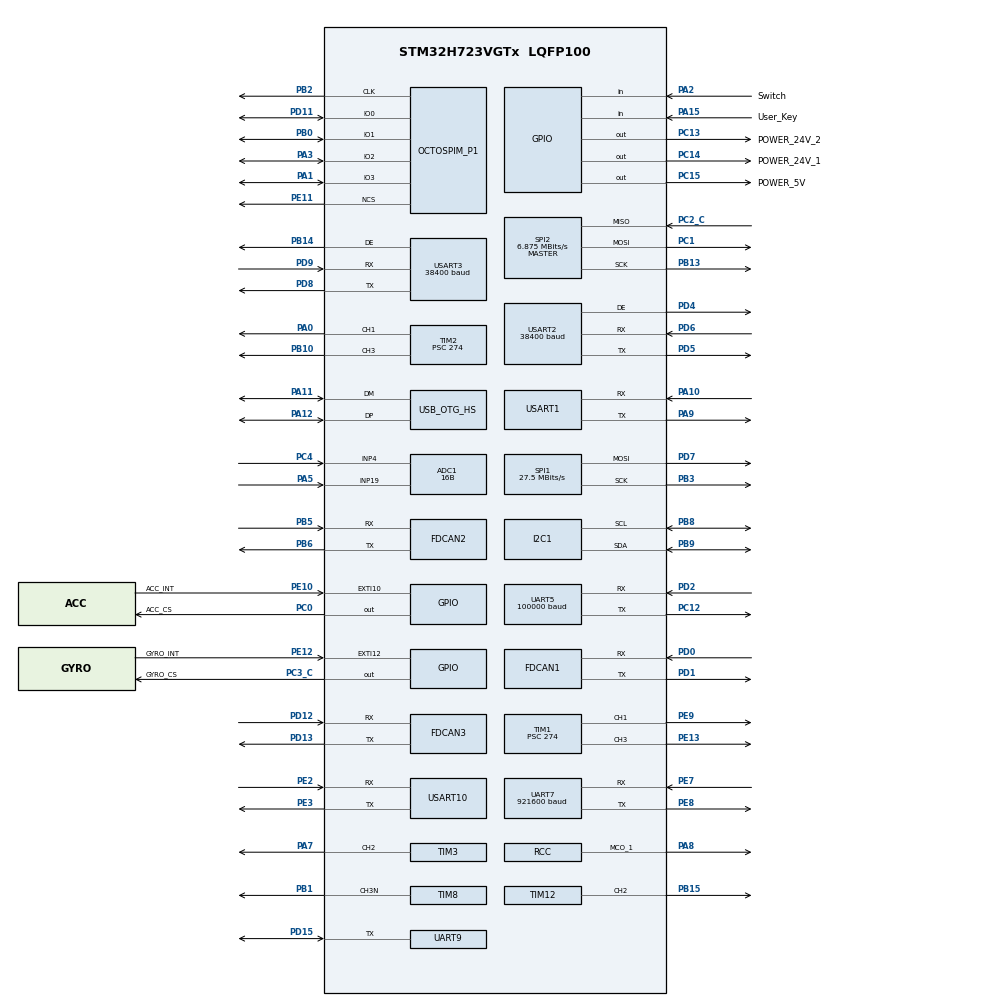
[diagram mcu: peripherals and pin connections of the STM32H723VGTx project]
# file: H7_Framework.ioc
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ADC1.Channel-0\#ChannelRegularConversion=ADC_CHANNEL_4
ADC1.Channel-1\#ChannelRegularConversion=ADC_CHANNEL_4
ADC1.ClockPrescaler=ADC_CLOCK_ASYNC_DIV64
ADC1.ContinuousConvMode=ENABLE
ADC1.DiscontinuousConvMode=DISABLE
ADC1.NbrOfConversion=2
ADC1.NbrOfConversionFlag=1
ADC1.OffsetNumber-0\#ChannelRegularConversion=ADC_OFFSET_NONE
ADC1.OffsetNumber-1\#ChannelRegularConversion=ADC_OFFSET_NONE
ADC1.OffsetSignedSaturation-0\#ChannelRegularConversion=DISABLE
ADC1.OffsetSignedSaturation-1\#ChannelRegularConversion=DISABLE
ADC1.Rank-0\#ChannelRegularConversion=1
ADC1.Rank-1\#ChannelRegularConversion=2
ADC1.Resolution=ADC_RESOLUTION_16B
ADC1.SamplingTime-0\#ChannelRegularConversion=ADC_SAMPLETIME_64CYCLES_5
ADC1.SamplingTime-1\#ChannelRegularConversion=ADC_SAMPLETIME_64CYCLES_5
ADC1.master=1
CORTEX_M7.CPU_ICache=Enabled
CORTEX_M7.default_mode_Activation=0
Dma.Request0=UART5_RX
Dma.Request1=SPI2_RX
Dma.Request10=USART2_RX
Dma.Request11=USART3_RX
Dma.Request12=USART2_TX
Dma.Request13=USART3_TX
Dma.Request14=UART9_RX
Dma.Request15=UART9_TX
Dma.Request2=SPI2_TX
Dma.Request3=TIM3_CH2
Dma.Request4=USART1_RX
Dma.Request5=UART7_RX
Dma.Request6=USART10_TX
Dma.Request7=USART10_RX
Dma.Request8=USART1_TX
Dma.Request9=UART7_TX
Dma.SPI2_RX.1.Direction=DMA_PERIPH_TO_MEMORY
Dma.SPI2_RX.1.EventEnable=DISABLE
Dma.SPI2_RX.1.FIFOMode=DMA_FIFOMODE_DISABLE
Dma.SPI2_RX.1.Instance=DMA1_Stream3
Dma.SPI2_RX.1.MemDataAlignment=DMA_MDATAALIGN_BYTE
Dma.SPI2_RX.1.MemInc=DMA_MINC_ENABLE
Dma.SPI2_RX.1.Mode=DMA_NORMAL
Dma.SPI2_RX.1.PeriphDataAlignment=DMA_PDATAALIGN_BYTE
Dma.SPI2_RX.1.PeriphInc=DMA_PINC_DISABLE
Dma.SPI2_RX.1.Polarity=HAL_DMAMUX_REQ_GEN_RISING
Dma.SPI2_RX.1.Priority=DMA_PRIORITY_VERY_HIGH
Dma.SPI2_RX.1.RequestNumber=1
Dma.SPI2_RX.1.SignalID=NONE
Dma.SPI2_RX.1.SyncEnable=DISABLE
Dma.SPI2_RX.1.SyncPolarity=HAL_DMAMUX_SYNC_NO_EVENT
Dma.SPI2_RX.1.SyncRequestNumber=1
Dma.SPI2_RX.1.SyncSignalID=NONE
Dma.SPI2_TX.2.Direction=DMA_MEMORY_TO_PERIPH
Dma.SPI2_TX.2.EventEnable=DISABLE
Dma.SPI2_TX.2.FIFOMode=DMA_FIFOMODE_DISABLE
Dma.SPI2_TX.2.Instance=DMA1_Stream4
Dma.SPI2_TX.2.MemDataAlignment=DMA_MDATAALIGN_BYTE
Dma.SPI2_TX.2.MemInc=DMA_MINC_ENABLE
Dma.SPI2_TX.2.Mode=DMA_NORMAL
Dma.SPI2_TX.2.PeriphDataAlignment=DMA_PDATAALIGN_BYTE
Dma.SPI2_TX.2.PeriphInc=DMA_PINC_DISABLE
Dma.SPI2_TX.2.Polarity=HAL_DMAMUX_REQ_GEN_RISING
Dma.SPI2_TX.2.Priority=DMA_PRIORITY_HIGH
Dma.SPI2_TX.2.RequestNumber=1
Dma.SPI2_TX.2.SignalID=NONE
Dma.SPI2_TX.2.SyncEnable=DISABLE
Dma.SPI2_TX.2.SyncPolarity=HAL_DMAMUX_SYNC_NO_EVENT
Dma.SPI2_TX.2.SyncRequestNumber=1
Dma.SPI2_TX.2.SyncSignalID=NONE
Dma.TIM3_CH2.3.Direction=DMA_MEMORY_TO_PERIPH
Dma.TIM3_CH2.3.EventEnable=DISABLE
Dma.TIM3_CH2.3.FIFOMode=DMA_FIFOMODE_DISABLE
Dma.TIM3_CH2.3.Instance=DMA1_Stream1
Dma.TIM3_CH2.3.MemDataAlignment=DMA_MDATAALIGN_HALFWORD
Dma.TIM3_CH2.3.MemInc=DMA_MINC_ENABLE
Dma.TIM3_CH2.3.Mode=DMA_CIRCULAR
Dma.TIM3_CH2.3.PeriphDataAlignment=DMA_PDATAALIGN_HALFWORD
Dma.TIM3_CH2.3.PeriphInc=DMA_PINC_DISABLE
Dma.TIM3_CH2.3.Polarity=HAL_DMAMUX_REQ_GEN_RISING
Dma.TIM3_CH2.3.Priority=DMA_PRIORITY_LOW
Dma.TIM3_CH2.3.RequestNumber=1
Dma.TIM3_CH2.3.SignalID=NONE
Dma.TIM3_CH2.3.SyncEnable=DISABLE
Dma.TIM3_CH2.3.SyncPolarity=HAL_DMAMUX_SYNC_NO_EVENT
Dma.TIM3_CH2.3.SyncRequestNumber=1
Dma.TIM3_CH2.3.SyncSignalID=NONE
Dma.UART5_RX.0.Direction=DMA_PERIPH_TO_MEMORY
Dma.UART5_RX.0.EventEnable=DISABLE
Dma.UART5_RX.0.FIFOMode=DMA_FIFOMODE_DISABLE
Dma.UART5_RX.0.Instance=DMA1_Stream0
Dma.UART5_RX.0.MemDataAlignment=DMA_MDATAALIGN_BYTE
Dma.UART5_RX.0.MemInc=DMA_MINC_ENABLE
Dma.UART5_RX.0.Mode=DMA_NORMAL
Dma.UART5_RX.0.PeriphDataAlignment=DMA_PDATAALIGN_BYTE
Dma.UART5_RX.0.PeriphInc=DMA_PINC_DISABLE
Dma.UART5_RX.0.Polarity=HAL_DMAMUX_REQ_GEN_RISING
Dma.UART5_RX.0.Priority=DMA_PRIORITY_HIGH
Dma.UART5_RX.0.RequestNumber=1
Dma.UART5_RX.0.SignalID=NONE
Dma.UART5_RX.0.SyncEnable=DISABLE
Dma.UART5_RX.0.SyncPolarity=HAL_DMAMUX_SYNC_NO_EVENT
Dma.UART5_RX.0.SyncRequestNumber=1
Dma.UART5_RX.0.SyncSignalID=NONE
Dma.UART7_RX.5.Direction=DMA_PERIPH_TO_MEMORY
Dma.UART7_RX.5.EventEnable=DISABLE
Dma.UART7_RX.5.FIFOMode=DMA_FIFOMODE_DISABLE
Dma.UART7_RX.5.Instance=DMA1_Stream5
Dma.UART7_RX.5.MemDataAlignment=DMA_MDATAALIGN_BYTE
Dma.UART7_RX.5.MemInc=DMA_MINC_ENABLE
Dma.UART7_RX.5.Mode=DMA_NORMAL
Dma.UART7_RX.5.PeriphDataAlignment=DMA_PDATAALIGN_BYTE
Dma.UART7_RX.5.PeriphInc=DMA_PINC_DISABLE
Dma.UART7_RX.5.Polarity=HAL_DMAMUX_REQ_GEN_RISING
Dma.UART7_RX.5.Priority=DMA_PRIORITY_LOW
Dma.UART7_RX.5.RequestNumber=1
Dma.UART7_RX.5.SignalID=NONE
Dma.UART7_RX.5.SyncEnable=DISABLE
Dma.UART7_RX.5.SyncPolarity=HAL_DMAMUX_SYNC_NO_EVENT
Dma.UART7_RX.5.SyncRequestNumber=1
Dma.UART7_RX.5.SyncSignalID=NONE
Dma.UART7_TX.9.Direction=DMA_MEMORY_TO_PERIPH
Dma.UART7_TX.9.EventEnable=DISABLE
Dma.UART7_TX.9.FIFOMode=DMA_FIFOMODE_DISABLE
Dma.UART7_TX.9.Instance=DMA2_Stream1
Dma.UART7_TX.9.MemDataAlignment=DMA_MDATAALIGN_BYTE
Dma.UART7_TX.9.MemInc=DMA_MINC_ENABLE
Dma.UART7_TX.9.Mode=DMA_NORMAL
Dma.UART7_TX.9.PeriphDataAlignment=DMA_PDATAALIGN_BYTE
Dma.UART7_TX.9.PeriphInc=DMA_PINC_DISABLE
Dma.UART7_TX.9.Polarity=HAL_DMAMUX_REQ_GEN_RISING
Dma.UART7_TX.9.Priority=DMA_PRIORITY_LOW
Dma.UART7_TX.9.RequestNumber=1
Dma.UART7_TX.9.SignalID=NONE
Dma.UART7_TX.9.SyncEnable=DISABLE
Dma.UART7_TX.9.SyncPolarity=HAL_DMAMUX_SYNC_NO_EVENT
Dma.UART7_TX.9.SyncRequestNumber=1
Dma.UART7_TX.9.SyncSignalID=NONE
Dma.UART9_RX.14.Direction=DMA_PERIPH_TO_MEMORY
Dma.UART9_RX.14.EventEnable=DISABLE
Dma.UART9_RX.14.FIFOMode=DMA_FIFOMODE_DISABLE
Dma.UART9_RX.14.Instance=DMA2_Stream6
Dma.UART9_RX.14.MemDataAlignment=DMA_MDATAALIGN_BYTE
Dma.UART9_RX.14.MemInc=DMA_MINC_ENABLE
Dma.UART9_RX.14.Mode=DMA_NORMAL
Dma.UART9_RX.14.PeriphDataAlignment=DMA_PDATAALIGN_BYTE
Dma.UART9_RX.14.PeriphInc=DMA_PINC_DISABLE
Dma.UART9_RX.14.Polarity=HAL_DMAMUX_REQ_GEN_RISING
Dma.UART9_RX.14.Priority=DMA_PRIORITY_HIGH
Dma.UART9_RX.14.RequestNumber=1
Dma.UART9_RX.14.SignalID=NONE
Dma.UART9_RX.14.SyncEnable=DISABLE
Dma.UART9_RX.14.SyncPolarity=HAL_DMAMUX_SYNC_NO_EVENT
Dma.UART9_RX.14.SyncRequestNumber=1
Dma.UART9_RX.14.SyncSignalID=NONE
Dma.UART9_TX.15.Direction=DMA_MEMORY_TO_PERIPH
Dma.UART9_TX.15.EventEnable=DISABLE
Dma.UART9_TX.15.FIFOMode=DMA_FIFOMODE_DISABLE
Dma.UART9_TX.15.Instance=DMA2_Stream7
Dma.UART9_TX.15.MemDataAlignment=DMA_MDATAALIGN_BYTE
Dma.UART9_TX.15.MemInc=DMA_MINC_ENABLE
Dma.UART9_TX.15.Mode=DMA_NORMAL
Dma.UART9_TX.15.PeriphDataAlignment=DMA_PDATAALIGN_BYTE
Dma.UART9_TX.15.PeriphInc=DMA_PINC_DISABLE
Dma.UART9_TX.15.Polarity=HAL_DMAMUX_REQ_GEN_RISING
Dma.UART9_TX.15.Priority=DMA_PRIORITY_HIGH
Dma.UART9_TX.15.RequestNumber=1
Dma.UART9_TX.15.SignalID=NONE
Dma.UART9_TX.15.SyncEnable=DISABLE
Dma.UART9_TX.15.SyncPolarity=HAL_DMAMUX_SYNC_NO_EVENT
Dma.UART9_TX.15.SyncRequestNumber=1
Dma.UART9_TX.15.SyncSignalID=NONE
Dma.USART10_RX.7.Direction=DMA_PERIPH_TO_MEMORY
Dma.USART10_RX.7.EventEnable=DISABLE
Dma.USART10_RX.7.FIFOMode=DMA_FIFOMODE_DISABLE
Dma.USART10_RX.7.Instance=DMA1_Stream7
Dma.USART10_RX.7.MemDataAlignment=DMA_MDATAALIGN_BYTE
Dma.USART10_RX.7.MemInc=DMA_MINC_ENABLE
Dma.USART10_RX.7.Mode=DMA_NORMAL
Dma.USART10_RX.7.PeriphDataAlignment=DMA_PDATAALIGN_BYTE
Dma.USART10_RX.7.PeriphInc=DMA_PINC_DISABLE
Dma.USART10_RX.7.Polarity=HAL_DMAMUX_REQ_GEN_RISING
Dma.USART10_RX.7.Priority=DMA_PRIORITY_LOW
Dma.USART10_RX.7.RequestNumber=1
Dma.USART10_RX.7.SignalID=NONE
Dma.USART10_RX.7.SyncEnable=DISABLE
Dma.USART10_RX.7.SyncPolarity=HAL_DMAMUX_SYNC_NO_EVENT
Dma.USART10_RX.7.SyncRequestNumber=1
Dma.USART10_RX.7.SyncSignalID=NONE
Dma.USART10_TX.6.Direction=DMA_MEMORY_TO_PERIPH
Dma.USART10_TX.6.EventEnable=DISABLE
Dma.USART10_TX.6.FIFOMode=DMA_FIFOMODE_DISABLE
Dma.USART10_TX.6.Instance=DMA1_Stream6
Dma.USART10_TX.6.MemDataAlignment=DMA_MDATAALIGN_BYTE
Dma.USART10_TX.6.MemInc=DMA_MINC_ENABLE
Dma.USART10_TX.6.Mode=DMA_NORMAL
Dma.USART10_TX.6.PeriphDataAlignment=DMA_PDATAALIGN_BYTE
Dma.USART10_TX.6.PeriphInc=DMA_PINC_DISABLE
Dma.USART10_TX.6.Polarity=HAL_DMAMUX_REQ_GEN_RISING
Dma.USART10_TX.6.Priority=DMA_PRIORITY_LOW
Dma.USART10_TX.6.RequestNumber=1
Dma.USART10_TX.6.SignalID=NONE
Dma.USART10_TX.6.SyncEnable=DISABLE
Dma.USART10_TX.6.SyncPolarity=HAL_DMAMUX_SYNC_NO_EVENT
Dma.USART10_TX.6.SyncRequestNumber=1
Dma.USART10_TX.6.SyncSignalID=NONE
Dma.USART1_RX.4.Direction=DMA_PERIPH_TO_MEMORY
Dma.USART1_RX.4.EventEnable=DISABLE
Dma.USART1_RX.4.FIFOMode=DMA_FIFOMODE_DISABLE
Dma.USART1_RX.4.Instance=DMA1_Stream2
Dma.USART1_RX.4.MemDataAlignment=DMA_MDATAALIGN_BYTE
Dma.USART1_RX.4.MemInc=DMA_MINC_ENABLE
Dma.USART1_RX.4.Mode=DMA_NORMAL
Dma.USART1_RX.4.PeriphDataAlignment=DMA_PDATAALIGN_BYTE
Dma.USART1_RX.4.PeriphInc=DMA_PINC_DISABLE
Dma.USART1_RX.4.Polarity=HAL_DMAMUX_REQ_GEN_RISING
Dma.USART1_RX.4.Priority=DMA_PRIORITY_LOW
Dma.USART1_RX.4.RequestNumber=1
Dma.USART1_RX.4.SignalID=NONE
Dma.USART1_RX.4.SyncEnable=DISABLE
Dma.USART1_RX.4.SyncPolarity=HAL_DMAMUX_SYNC_NO_EVENT
Dma.USART1_RX.4.SyncRequestNumber=1
Dma.USART1_RX.4.SyncSignalID=NONE
Dma.USART1_TX.8.Direction=DMA_MEMORY_TO_PERIPH
Dma.USART1_TX.8.EventEnable=DISABLE
Dma.USART1_TX.8.FIFOMode=DMA_FIFOMODE_DISABLE
Dma.USART1_TX.8.Instance=DMA2_Stream0
Dma.USART1_TX.8.MemDataAlignment=DMA_MDATAALIGN_BYTE
Dma.USART1_TX.8.MemInc=DMA_MINC_ENABLE
Dma.USART1_TX.8.Mode=DMA_NORMAL
Dma.USART1_TX.8.PeriphDataAlignment=DMA_PDATAALIGN_BYTE
Dma.USART1_TX.8.PeriphInc=DMA_PINC_DISABLE
Dma.USART1_TX.8.Polarity=HAL_DMAMUX_REQ_GEN_RISING
Dma.USART1_TX.8.Priority=DMA_PRIORITY_LOW
Dma.USART1_TX.8.RequestNumber=1
Dma.USART1_TX.8.SignalID=NONE
Dma.USART1_TX.8.SyncEnable=DISABLE
Dma.USART1_TX.8.SyncPolarity=HAL_DMAMUX_SYNC_NO_EVENT
Dma.USART1_TX.8.SyncRequestNumber=1
Dma.USART1_TX.8.SyncSignalID=NONE
Dma.USART2_RX.10.Direction=DMA_PERIPH_TO_MEMORY
Dma.USART2_RX.10.EventEnable=DISABLE
Dma.USART2_RX.10.FIFOMode=DMA_FIFOMODE_DISABLE
Dma.USART2_RX.10.Instance=DMA2_Stream2
Dma.USART2_RX.10.MemDataAlignment=DMA_MDATAALIGN_BYTE
Dma.USART2_RX.10.MemInc=DMA_MINC_ENABLE
Dma.USART2_RX.10.Mode=DMA_NORMAL
Dma.USART2_RX.10.PeriphDataAlignment=DMA_PDATAALIGN_BYTE
Dma.USART2_RX.10.PeriphInc=DMA_PINC_DISABLE
Dma.USART2_RX.10.Polarity=HAL_DMAMUX_REQ_GEN_RISING
Dma.USART2_RX.10.Priority=DMA_PRIORITY_HIGH
Dma.USART2_RX.10.RequestNumber=1
Dma.USART2_RX.10.SignalID=NONE
Dma.USART2_RX.10.SyncEnable=DISABLE
Dma.USART2_RX.10.SyncPolarity=HAL_DMAMUX_SYNC_NO_EVENT
Dma.USART2_RX.10.SyncRequestNumber=1
Dma.USART2_RX.10.SyncSignalID=NONE
Dma.USART2_TX.12.Direction=DMA_MEMORY_TO_PERIPH
Dma.USART2_TX.12.EventEnable=DISABLE
Dma.USART2_TX.12.FIFOMode=DMA_FIFOMODE_DISABLE
Dma.USART2_TX.12.Instance=DMA2_Stream4
Dma.USART2_TX.12.MemDataAlignment=DMA_MDATAALIGN_BYTE
Dma.USART2_TX.12.MemInc=DMA_MINC_ENABLE
Dma.USART2_TX.12.Mode=DMA_NORMAL
Dma.USART2_TX.12.PeriphDataAlignment=DMA_PDATAALIGN_BYTE
Dma.USART2_TX.12.PeriphInc=DMA_PINC_DISABLE
Dma.USART2_TX.12.Polarity=HAL_DMAMUX_REQ_GEN_RISING
Dma.USART2_TX.12.Priority=DMA_PRIORITY_LOW
Dma.USART2_TX.12.RequestNumber=1
Dma.USART2_TX.12.SignalID=NONE
Dma.USART2_TX.12.SyncEnable=DISABLE
Dma.USART2_TX.12.SyncPolarity=HAL_DMAMUX_SYNC_NO_EVENT
Dma.USART2_TX.12.SyncRequestNumber=1
Dma.USART2_TX.12.SyncSignalID=NONE
Dma.USART3_RX.11.Direction=DMA_PERIPH_TO_MEMORY
Dma.USART3_RX.11.EventEnable=DISABLE
Dma.USART3_RX.11.FIFOMode=DMA_FIFOMODE_DISABLE
Dma.USART3_RX.11.Instance=DMA2_Stream3
Dma.USART3_RX.11.MemDataAlignment=DMA_MDATAALIGN_BYTE
Dma.USART3_RX.11.MemInc=DMA_MINC_ENABLE
Dma.USART3_RX.11.Mode=DMA_NORMAL
Dma.USART3_RX.11.PeriphDataAlignment=DMA_PDATAALIGN_BYTE
Dma.USART3_RX.11.PeriphInc=DMA_PINC_DISABLE
Dma.USART3_RX.11.Polarity=HAL_DMAMUX_REQ_GEN_RISING
Dma.USART3_RX.11.Priority=DMA_PRIORITY_HIGH
Dma.USART3_RX.11.RequestNumber=1
Dma.USART3_RX.11.SignalID=NONE
Dma.USART3_RX.11.SyncEnable=DISABLE
Dma.USART3_RX.11.SyncPolarity=HAL_DMAMUX_SYNC_NO_EVENT
Dma.USART3_RX.11.SyncRequestNumber=1
Dma.USART3_RX.11.SyncSignalID=NONE
Dma.USART3_TX.13.Direction=DMA_MEMORY_TO_PERIPH
Dma.USART3_TX.13.EventEnable=DISABLE
Dma.USART3_TX.13.FIFOMode=DMA_FIFOMODE_DISABLE
Dma.USART3_TX.13.Instance=DMA2_Stream5
Dma.USART3_TX.13.MemDataAlignment=DMA_MDATAALIGN_BYTE
Dma.USART3_TX.13.MemInc=DMA_MINC_ENABLE
Dma.USART3_TX.13.Mode=DMA_NORMAL
Dma.USART3_TX.13.PeriphDataAlignment=DMA_PDATAALIGN_BYTE
Dma.USART3_TX.13.PeriphInc=DMA_PINC_DISABLE
Dma.USART3_TX.13.Polarity=HAL_DMAMUX_REQ_GEN_RISING
Dma.USART3_TX.13.Priority=DMA_PRIORITY_LOW
Dma.USART3_TX.13.RequestNumber=1
Dma.USART3_TX.13.SignalID=NONE
Dma.USART3_TX.13.SyncEnable=DISABLE
Dma.USART3_TX.13.SyncPolarity=HAL_DMAMUX_SYNC_NO_EVENT
Dma.USART3_TX.13.SyncRequestNumber=1
Dma.USART3_TX.13.SyncSignalID=NONE
FDCAN1.AutoRetransmission=ENABLE
FDCAN1.CalculateBaudRateNominal=999999
FDCAN1.CalculateTimeBitNominal=1000
FDCAN1.CalculateTimeQuantumNominal=100.00000000000001
FDCAN1.DataTimeSeg1=16
FDCAN1.DataTimeSeg2=5
FDCAN1.NominalPrescaler=11
FDCAN1.NominalTimeSeg1=7
FDCAN1.NominalTimeSeg2=2
FDCAN1.ProtocolException=ENABLE
FDCAN1.RxBufferSize=FDCAN_DATA_BYTES_64
FDCAN1.RxFifo0ElmtSize=FDCAN_DATA_BYTES_64
FDCAN1.RxFifo0ElmtsNbr=8
FDCAN1.RxFifo1ElmtSize=FDCAN_DATA_BYTES_64
FDCAN1.RxFifo1ElmtsNbr=0
FDCAN1.StdFiltersNbr=1
FDCAN1.TxElmtSize=FDCAN_DATA_BYTES_64
FDCAN1.TxFifoQueueElmtsNbr=8
FDCAN2.AutoRetransmission=ENABLE
FDCAN2.CalculateBaudRateNominal=999999
FDCAN2.CalculateTimeBitNominal=1000
FDCAN2.CalculateTimeQuantumNominal=100.00000000000001
FDCAN2.DataTimeSeg1=16
FDCAN2.DataTimeSeg2=5
FDCAN2.MessageRAMOffset=853
FDCAN2.NominalPrescaler=11
FDCAN2.NominalTimeSeg1=7
FDCAN2.NominalTimeSeg2=2
FDCAN2.ProtocolException=ENABLE
FDCAN2.RxBufferSize=FDCAN_DATA_BYTES_64
FDCAN2.RxFifo0ElmtSize=FDCAN_DATA_BYTES_64
FDCAN2.RxFifo0ElmtsNbr=0
FDCAN2.RxFifo1ElmtSize=FDCAN_DATA_BYTES_64
FDCAN2.RxFifo1ElmtsNbr=8
FDCAN2.StdFiltersNbr=1
FDCAN2.TxElmtSize=FDCAN_DATA_BYTES_64
FDCAN2.TxFifoQueueElmtsNbr=8
FDCAN3.AutoRetransmission=ENABLE
FDCAN3.CalculateBaudRateNominal=999999
FDCAN3.CalculateTimeBitNominal=1000
FDCAN3.CalculateTimeQuantumNominal=100.00000000000001
FDCAN3.DataTimeSeg1=16
FDCAN3.DataTimeSeg2=5
FDCAN3.MessageRAMOffset=1706
FDCAN3.NominalPrescaler=11
FDCAN3.NominalTimeSeg1=7
FDCAN3.NominalTimeSeg2=2
FDCAN3.ProtocolException=ENABLE
FDCAN3.RxBufferSize=FDCAN_DATA_BYTES_64
FDCAN3.RxFifo0ElmtSize=FDCAN_DATA_BYTES_64
FDCAN3.RxFifo0ElmtsNbr=8
FDCAN3.RxFifo1ElmtSize=FDCAN_DATA_BYTES_64
FDCAN3.StdFiltersNbr=1
FDCAN3.TxElmtSize=FDCAN_DATA_BYTES_64
FDCAN3.TxFifoQueueElmtsNbr=8
FREERTOS.Tasks01=IMU,48,256,IMU_Task,As weak,NULL,Dynamic,NULL,NULL;Motor,32,256,Motor_Task,As weak,NULL,Dynamic,NULL,NULL;Command,41,128,Command_Task,As weak,NULL,Dynamic,NULL,NULL;Task01,25,512,StartTask01,As weak,NULL,Dynamic,NULL,NULL;Task02,26,512,StartTask02,As weak,NULL,Dynamic,NULL,NULL;RtosSnapshot,8,256,RtosSnapshotTask,As weak,NULL,Dynamic,NULL,NULL
I2C1.Timing=0x60404E72
Mcu.Family=STM32H7
Mcu.Name=STM32H723VGTx
Mcu.Package=LQFP100
NVIC.ADC_IRQn=true\:5\:0\:false\:false\:true\:true\:true\:true\:true
NVIC.DMA1_Stream0_IRQn=true\:5\:0\:false\:false\:true\:true\:false\:true\:true
NVIC.DMA1_Stream1_IRQn=true\:5\:0\:false\:false\:true\:true\:false\:true\:true
NVIC.DMA1_Stream2_IRQn=true\:5\:0\:false\:false\:true\:true\:false\:true\:true
NVIC.DMA1_Stream3_IRQn=true\:5\:0\:false\:false\:true\:true\:false\:true\:true
NVIC.DMA1_Stream4_IRQn=true\:5\:0\:false\:false\:true\:true\:false\:true\:true
NVIC.DMA1_Stream5_IRQn=true\:5\:0\:false\:false\:true\:true\:false\:true\:true
NVIC.DMA1_Stream6_IRQn=true\:5\:0\:false\:false\:true\:true\:false\:true\:true
NVIC.DMA1_Stream7_IRQn=true\:5\:0\:false\:false\:true\:true\:false\:true\:true
NVIC.DMA2_Stream0_IRQn=true\:5\:0\:false\:false\:true\:true\:false\:true\:true
NVIC.DMA2_Stream1_IRQn=true\:5\:0\:false\:false\:true\:true\:false\:true\:true
NVIC.DMA2_Stream2_IRQn=true\:5\:0\:false\:false\:true\:true\:false\:true\:true
NVIC.DMA2_Stream3_IRQn=true\:5\:0\:false\:false\:true\:true\:false\:true\:true
NVIC.DMA2_Stream4_IRQn=true\:5\:0\:false\:false\:true\:true\:false\:true\:true
NVIC.DMA2_Stream5_IRQn=true\:5\:0\:false\:false\:true\:true\:false\:true\:true
NVIC.DMA2_Stream6_IRQn=true\:5\:0\:false\:false\:true\:true\:false\:true\:true
NVIC.DMA2_Stream7_IRQn=true\:5\:0\:false\:false\:true\:true\:false\:true\:true
NVIC.EXTI15_10_IRQn=true\:5\:0\:false\:false\:true\:true\:true\:true\:true
NVIC.FDCAN1_IT0_IRQn=true\:5\:0\:false\:false\:true\:true\:true\:true\:true
NVIC.FDCAN1_IT1_IRQn=true\:5\:0\:false\:false\:true\:true\:true\:true\:true
NVIC.FDCAN2_IT0_IRQn=true\:5\:0\:false\:false\:true\:true\:true\:true\:true
NVIC.FDCAN2_IT1_IRQn=true\:5\:0\:false\:false\:true\:true\:true\:true\:true
NVIC.FDCAN3_IT0_IRQn=true\:5\:0\:false\:false\:true\:true\:true\:true\:true
NVIC.FDCAN3_IT1_IRQn=true\:5\:0\:false\:false\:true\:true\:true\:true\:true
NVIC.OTG_HS_IRQn=true\:5\:0\:false\:false\:true\:true\:false\:true\:true
NVIC.PriorityGroup=NVIC_PRIORITYGROUP_4
NVIC.SPI2_IRQn=true\:5\:0\:false\:false\:true\:true\:false\:true\:true
NVIC.TIM17_IRQn=true\:15\:0\:false\:false\:true\:false\:false\:true\:true
NVIC.TIM4_IRQn=true\:5\:0\:false\:false\:true\:true\:true\:true\:true
NVIC.TIM6_DAC_IRQn=true\:5\:0\:false\:false\:true\:true\:true\:true\:true
NVIC.TIM7_IRQn=true\:5\:0\:false\:false\:true\:true\:true\:true\:true
NVIC.TimeBase=TIM17_IRQn
NVIC.TimeBaseIP=TIM17
NVIC.UART5_IRQn=true\:5\:0\:false\:false\:true\:true\:true\:true\:true
NVIC.UART7_IRQn=true\:5\:0\:false\:false\:true\:true\:true\:true\:true
NVIC.UART9_IRQn=true\:5\:0\:false\:false\:true\:true\:true\:true\:true
NVIC.USART10_IRQn=true\:5\:0\:false\:false\:true\:true\:true\:true\:true
NVIC.USART1_IRQn=true\:5\:0\:false\:false\:true\:true\:true\:true\:true
NVIC.USART2_IRQn=true\:5\:0\:false\:false\:true\:true\:true\:true\:true
NVIC.USART3_IRQn=true\:5\:0\:false\:false\:true\:true\:true\:true\:true
OCTOSPI2.ClockMode=HAL_OSPI_CLOCK_MODE_3
OCTOSPI2.ClockPrescaler=3
OCTOSPI2.DeviceSize=23
OCTOSPI2.FifoThreshold=8
OCTOSPI2.SampleShifting=HAL_OSPI_SAMPLE_SHIFTING_HALFCYCLE
PA0.Signal=S_TIM2_CH1_ETR
PA1.Mode=OCTOSPI2_IOL_Port1L
PA1.Signal=OCTOSPIM_P1_IO3
PA10.Mode=Asynchronous
PA10.Signal=USART1_RX
PA11.Mode=Device_Only_FS
PA11.Signal=USB_OTG_HS_DM
PA12.Mode=Device_Only_FS
PA12.Signal=USB_OTG_HS_DP
PA13(JTMS/SWDIO).Mode=Serial_Wire
PA13(JTMS/SWDIO).Signal=DEBUG_JTMS-SWDIO
PA14(JTCK/SWCLK).Mode=Serial_Wire
PA14(JTCK/SWCLK).Signal=DEBUG_JTCK-SWCLK
PA15(JTDI).GPIO_Label=User_Key
PA15(JTDI).GPIO_PuPd=GPIO_PULLUP
PA15(JTDI).Signal=GPIO_Input
PA2.GPIO_Label=Switch
PA2.GPIO_PuPd=GPIO_PULLUP
PA2.Signal=GPIO_Input
PA3.Mode=OCTOSPI2_IOL_Port1L
PA3.Signal=OCTOSPIM_P1_IO2
PA5.Signal=ADCx_INP19
PA7.Signal=S_TIM3_CH2
PA8.Mode=Clock-out-1
PA8.Signal=RCC_MCO_1
PA9.Mode=Asynchronous
PA9.Signal=USART1_TX
PB0.Mode=OCTOSPI2_IOL_Port1L
PB0.Signal=OCTOSPIM_P1_IO1
PB1.Mode=PWM Generation3 CH3N
PB1.Signal=TIM8_CH3N
PB10.Signal=S_TIM2_CH3
PB13.Mode=Full_Duplex_Master
PB13.Signal=SPI2_SCK
PB14.Mode=Hardware Flow Control (RS485)
PB14.Signal=USART3_DE
PB15.Signal=S_TIM12_CH2
PB2.Mode=O2_P1_CLK
PB2.Signal=OCTOSPIM_P1_CLK
PB3(JTDO/TRACESWO).Mode=TX_Only_Simplex_Unidirect_Master
PB3(JTDO/TRACESWO).Signal=SPI1_SCK
PB5.GPIO_Speed=GPIO_SPEED_FREQ_VERY_HIGH
PB5.Mode=FDCAN_Activate
PB5.Signal=FDCAN2_RX
PB6.GPIO_Speed=GPIO_SPEED_FREQ_VERY_HIGH
PB6.Mode=FDCAN_Activate
PB6.Signal=FDCAN2_TX
PB8.Mode=I2C
PB8.Signal=I2C1_SCL
PB9.Mode=I2C
PB9.Signal=I2C1_SDA
PC0.GPIO_Label=ACC_CS
PC0.GPIO_Speed=GPIO_SPEED_FREQ_VERY_HIGH
PC0.PinState=GPIO_PIN_SET
PC0.Signal=GPIO_Output
PC1.Mode=Full_Duplex_Master
PC1.Signal=SPI2_MOSI
PC12.Mode=Asynchronous
PC12.Signal=UART5_TX
PC13.GPIO_Label=POWER_24V_2
PC13.PinState=GPIO_PIN_SET
PC13.Signal=GPIO_Output
PC14-OSC32_IN.GPIO_Label=POWER_24V_1
PC14-OSC32_IN.PinState=GPIO_PIN_SET
PC14-OSC32_IN.Signal=GPIO_Output
PC15-OSC32_OUT.GPIO_Label=POWER_5V
PC15-OSC32_OUT.Signal=GPIO_Output
PC2_C.Mode=Full_Duplex_Master
PC2_C.Signal=SPI2_MISO
PC3_C.GPIO_Label=GYRO_CS
PC3_C.GPIO_Speed=GPIO_SPEED_FREQ_VERY_HIGH
PC3_C.PinState=GPIO_PIN_SET
PC3_C.Signal=GPIO_Output
PC4.Signal=ADCx_INP4
PD0.GPIO_Speed=GPIO_SPEED_FREQ_VERY_HIGH
PD0.Mode=FDCAN_Activate
PD0.Signal=FDCAN1_RX
PD1.GPIO_Speed=GPIO_SPEED_FREQ_VERY_HIGH
PD1.Mode=FDCAN_Activate
PD1.Signal=FDCAN1_TX
PD11.Mode=OCTOSPI2_IOL_Port1L
PD11.Signal=OCTOSPIM_P1_IO0
PD12.GPIO_Speed=GPIO_SPEED_FREQ_VERY_HIGH
PD12.Mode=FDCAN_Activate
PD12.Signal=FDCAN3_RX
PD13.GPIO_Speed=GPIO_SPEED_FREQ_VERY_HIGH
PD13.Mode=FDCAN_Activate
PD13.Signal=FDCAN3_TX
PD15.GPIO_ModeDefaultOD=GPIO_MODE_AF_PP
PD15.GPIO_PuPd=GPIO_PULLUP
PD15.GPIO_Speed=GPIO_SPEED_FREQ_VERY_HIGH
PD15.Mode=Half_duplex(single_wire_mode)
PD15.Signal=UART9_TX
PD2.GPIO_PuPd=GPIO_PULLUP
PD2.GPIO_Speed=GPIO_SPEED_FREQ_HIGH
PD2.Mode=Asynchronous
PD2.Signal=UART5_RX
PD4.Mode=Hardware Flow Control (RS485)
PD4.Signal=USART2_DE
PD5.Mode=Asynchronous
PD5.Signal=USART2_TX
PD6.Mode=Asynchronous
PD6.Signal=USART2_RX
PD7.Mode=TX_Only_Simplex_Unidirect_Master
PD7.Signal=SPI1_MOSI
PD8.Mode=Asynchronous
PD8.Signal=USART3_TX
PD9.Mode=Asynchronous
PD9.Signal=USART3_RX
PE10.GPIO_Label=ACC_INT
PE10.GPIO_ModeDefaultEXTI=GPIO_MODE_IT_FALLING
PE10.Signal=GPXTI10
PE11.Mode=OCTOSPI2_Port1_NCS
PE11.Signal=OCTOSPIM_P1_NCS
PE12.GPIO_Label=GYRO_INT
PE12.GPIO_ModeDefaultEXTI=GPIO_MODE_IT_FALLING
PE12.GPIO_PuPd=GPIO_PULLUP
PE12.Signal=GPXTI12
PE13.Signal=S_TIM1_CH3
PE2.Mode=Asynchronous
PE2.Signal=USART10_RX
PE3.Mode=Asynchronous
PE3.Signal=USART10_TX
PE7.Mode=Asynchronous
PE7.Signal=UART7_RX
PE8.GPIO_PuPd=GPIO_PULLUP
PE8.GPIO_Speed=GPIO_SPEED_FREQ_VERY_HIGH
PE8.Mode=Asynchronous
PE8.Signal=UART7_TX
PE9.Signal=S_TIM1_CH1
PH0-OSC_IN.Mode=HSE-External-Oscillator
PH0-OSC_IN.Signal=RCC_OSC_IN
PH1-OSC_OUT.Mode=HSE-External-Oscillator
PH1-OSC_OUT.Signal=RCC_OSC_OUT
ProjectManager.HeapSize=0x400
ProjectManager.StackSize=0x800
ProjectManager.TargetToolchain=CMake
RCC.ADCFreq_Value=96000000
RCC.APB1Freq_Value=137500000
RCC.APB2Freq_Value=137500000
RCC.APB3Freq_Value=137500000
RCC.APB4Freq_Value=137500000
RCC.CortexFreq_Value=550000000
RCC.D1PPRE=RCC_APB3_DIV2
RCC.D2PPRE1=RCC_APB1_DIV2
RCC.D2PPRE2=RCC_APB2_DIV2
RCC.D3PPRE=RCC_APB4_DIV2
RCC.DIVM1=3
RCC.DIVM2=2
RCC.DIVN1=68
RCC.DIVN2=16
RCC.DIVP1=1
RCC.DIVQ1=5
RCC.HCLKFreq_Value=275000000
RCC.HPRE=RCC_HCLK_DIV2
RCC.HSE_VALUE=24000000
RCC.PLL2FRACN=0
RCC.PLL3FRACN=0
RCC.PLLFRACN=6144
RCC.PLLSourceVirtual=RCC_PLLSOURCE_HSE
RCC.SYSCLKFreq_VALUE=550000000
RCC.SYSCLKSource=RCC_SYSCLKSOURCE_PLLCLK
RCC.USBCLockSelection=RCC_USBCLKSOURCE_HSI48
RCC.USBFreq_Value=48000000
SH.ADCx_INP19.0=ADC1_INP19,IN19-Single-Ended
SH.ADCx_INP4.0=ADC1_INP4,IN4-Single-Ended
SH.S_TIM12_CH2.0=TIM12_CH2,PWM Generation2 CH2
SH.S_TIM1_CH1.0=TIM1_CH1,PWM Generation1 CH1
SH.S_TIM1_CH3.0=TIM1_CH3,PWM Generation3 CH3
SH.S_TIM2_CH1_ETR.0=TIM2_CH1,PWM Generation1 CH1
SH.S_TIM2_CH3.0=TIM2_CH3,PWM Generation3 CH3
SH.S_TIM3_CH2.0=TIM3_CH2,PWM Generation2 CH2
SPI1.BaudRatePrescaler=SPI_BAUDRATEPRESCALER_4
SPI1.CLKPolarity=SPI_POLARITY_HIGH
SPI1.CalculateBaudRate=27.5 MBits/s
SPI1.DataSize=SPI_DATASIZE_8BIT
SPI1.Direction=SPI_DIRECTION_2LINES_TXONLY
SPI1.Mode=SPI_MODE_MASTER
SPI1.VirtualType=VM_MASTER
SPI2.BaudRatePrescaler=SPI_BAUDRATEPRESCALER_16
SPI2.CLKPhase=SPI_PHASE_2EDGE
SPI2.CLKPolarity=SPI_POLARITY_HIGH
SPI2.CalculateBaudRate=6.875 MBits/s
SPI2.DataSize=SPI_DATASIZE_8BIT
SPI2.Direction=SPI_DIRECTION_2LINES
SPI2.Mode=SPI_MODE_MASTER
SPI2.NSSPMode=SPI_NSS_PULSE_ENABLE
SPI2.VirtualType=VM_MASTER
TIM1.Channel-PWM\ Generation1\ CH1=TIM_CHANNEL_1
TIM1.Channel-PWM\ Generation3\ CH3=TIM_CHANNEL_3
TIM1.Period=19999
TIM1.Prescaler=274
TIM12.AutoReloadPreload=TIM_AUTORELOAD_PRELOAD_ENABLE
TIM12.Channel-PWM\ Generation2\ CH2=TIM_CHANNEL_2
TIM12.Period=420
TIM12.Prescaler=274
TIM2.Channel-PWM\ Generation1\ CH1=TIM_CHANNEL_1
TIM2.Channel-PWM\ Generation3\ CH3=TIM_CHANNEL_3
TIM2.Period=19999
TIM2.Prescaler=274
TIM3.Channel-PWM\ Generation2\ CH2=TIM_CHANNEL_2
TIM3.Period=343
TIM3.Prescaler=0
TIM4.Period=999
TIM4.Prescaler=274
TIM6.Period=1999
TIM6.Prescaler=274
TIM7.Period=4999
TIM7.Prescaler=274
TIM8.BreakPolarity=TIM_BREAKPOLARITY_LOW
TIM8.Channel-PWM\ Generation3\ CH3N=TIM_CHANNEL_3
TIM8.Period=9999
TIM8.Prescaler=274
UART5.BaudRate=100000
UART5.FIFOMode=FIFOMODE_ENABLE
UART5.Mode=MODE_RX
UART5.Parity=PARITY_EVEN
UART5.RxPinLevelInvertParam=UART_ADVFEATURE_RXINV_DISABLE
UART5.WordLength=WORDLENGTH_9B
UART7.BaudRate=921600
UART7.FIFOMode=FIFOMODE_ENABLE
UART9.BaudRate=6000000
USART1.VirtualMode-Asynchronous=VM_ASYNC
USART10.VirtualMode=VM_ASYNC
USART2.BaudRate=38400
USART2.VirtualMode-Asynchronous=VM_ASYNC
USART2.VirtualMode-Hardware\ Flow\ Control\ (RS485)=VM_ASYNC
USART3.BaudRate=38400
USART3.VirtualMode-Asynchronous=VM_ASYNC
USART3.VirtualMode-Hardware\ Flow\ Control\ (RS485)=VM_ASYNC
USB_DEVICE.CLASS_NAME_HS=CDC
USB_DEVICE.VirtualMode=Cdc
USB_DEVICE.VirtualModeHS=Cdc_HS
USB_OTG_HS.VirtualMode-Device_Only_FS=Device_Only_FS
VP_CORDIC_VS_CORDIC.Mode=CORDIC_Activate
VP_FREERTOS_VS_CMSIS_V2.Mode=CMSIS_V2
VP_MEMORYMAP_VS_MEMORYMAP.Mode=CurAppReg
VP_OCTOSPI2_VS_quad.Mode=quad_mode
VP_SYS_VS_tim17.Mode=TIM17
VP_TIM12_VS_ClockSourceINT.Mode=Internal
VP_TIM1_VS_ClockSourceINT.Mode=Internal
VP_TIM2_VS_ClockSourceINT.Mode=Internal
VP_TIM3_VS_ClockSourceINT.Mode=Internal
VP_TIM4_VS_ClockSourceINT.Mode=Internal
VP_TIM6_VS_ClockSourceINT.Mode=Enable_Timer
VP_TIM7_VS_ClockSourceINT.Mode=Enable_Timer
VP_TIM8_VS_ClockSourceINT.Mode=Internal
VP_USB_DEVICE_VS_USB_DEVICE_CDC_HS.Mode=CDC_HS
board=custom

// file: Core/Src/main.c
/* USER CODE BEGIN Header */
/**
  ******************************************************************************
  * @file           : main.c
  * @brief          : Main program body
  ******************************************************************************
  * @attention
  *
  * Copyright (c) 2026 STMicroelectronics.
  * All rights reserved.
  *
  * This software is licensed under terms that can be found in the LICENSE file
  * in the root directory of this software component.
  * If no LICENSE file comes with this software, it is provided AS-IS.
  *
  ******************************************************************************
  */
/* USER CODE END Header */
#include "main.h"
#include "FreeRTOS.h"
#include "cmsis_os2.h"
#include "adc.h"
#include "cordic.h"
#include "dma.h"
#include "fdcan.h"
#include "i2c.h"
#include "octospi.h"
#include "spi.h"
#include "tim.h"
#include "usart.h"
#include "usb_device.h"
#include "gpio.h"

/* USER CODE BEGIN PD */
extern void MY_TIM_PeriodElapsedCallback(TIM_HandleTypeDef *htim);
extern void System_Init(void);
/* USER CODE END PD */

void SystemClock_Config(void);
void MX_FREERTOS_Init(void);

int main(void)
{

  /* Enable the CPU Cache */

  /* Enable I-Cache---------------------------------------------------------*/
  SCB_EnableICache();

  /* MCU Configuration--------------------------------------------------------*/

  /* Reset of all peripherals, Initializes the Flash interface and the Systick. */
  HAL_Init();

  /* USER CODE BEGIN Init */
  SCB->CPACR |= ((3UL << 10*2)|(3UL << 11*2));
  __DSB(); __ISB();
  /* USER CODE END Init */

  /* Configure the system clock */
  SystemClock_Config();

  /* USER CODE BEGIN SysInit */
  SysTick_Config(SystemCoreClock / 1000);
  /* USER CODE END SysInit */

  /* Initialize all configured peripherals */
  MX_GPIO_Init();
  MX_DMA_Init();
  MX_FDCAN1_Init();
  MX_FDCAN2_Init();
  MX_FDCAN3_Init();
  MX_UART5_Init();
  MX_TIM3_Init();
  MX_TIM2_Init();
  MX_TIM4_Init();
  MX_SPI2_Init();
  MX_CORDIC_Init();
  MX_TIM12_Init();
  MX_UART7_Init();
  MX_USART1_UART_Init();
  MX_USART10_UART_Init();
  MX_TIM8_Init();
  MX_TIM6_Init();
  MX_TIM7_Init();
  MX_USART2_UART_Init();
  MX_USART3_UART_Init();
  MX_UART9_Init();
  MX_I2C1_Init();
  MX_TIM1_Init();
  MX_ADC1_Init();
  MX_OCTOSPI2_Init();
  MX_SPI1_Init();
  /* USER CODE BEGIN 2 */
  MX_USB_DEVICE_Init();
  System_Init();
  /* USER CODE END 2 */

  /* Init scheduler */
  osKernelInitialize();  /* Call init function for freertos objects (in cmsis_os2.c) */
  MX_FREERTOS_Init();

  /* Start scheduler */
  osKernelStart();

  /* We should never get here as control is now taken by the scheduler */

  /* Infinite loop */
  while (1)
  {

  }
}

void SystemClock_Config(void)
{
  RCC_OscInitTypeDef RCC_OscInitStruct = {0};
  RCC_ClkInitTypeDef RCC_ClkInitStruct = {0};

  /** Supply configuration update enable
  */
  HAL_PWREx_ConfigSupply(PWR_LDO_SUPPLY);

  /** Configure the main internal regulator output voltage
  */
  __HAL_PWR_VOLTAGESCALING_CONFIG(PWR_REGULATOR_VOLTAGE_SCALE0);

  while(!__HAL_PWR_GET_FLAG(PWR_FLAG_VOSRDY)) {}

  /** Initializes the RCC Oscillators according to the specified parameters
  * in the RCC_OscInitTypeDef structure.
  */
  RCC_OscInitStruct.OscillatorType = RCC_OSCILLATORTYPE_HSI48|RCC_OSCILLATORTYPE_HSI
                              |RCC_OSCILLATORTYPE_HSE;
  RCC_OscInitStruct.HSEState = RCC_HSE_ON;
  RCC_OscInitStruct.HSIState = RCC_HSI_DIV1;
  RCC_OscInitStruct.HSICalibrationValue = 64;
  RCC_OscInitStruct.HSI48State = RCC_HSI48_ON;
  RCC_OscInitStruct.PLL.PLLState = RCC_PLL_ON;
  RCC_OscInitStruct.PLL.PLLSource = RCC_PLLSOURCE_HSE;
  RCC_OscInitStruct.PLL.PLLM = 3;
  RCC_OscInitStruct.PLL.PLLN = 68;
  RCC_OscInitStruct.PLL.PLLP = 1;
  RCC_OscInitStruct.PLL.PLLQ = 5;
  RCC_OscInitStruct.PLL.PLLR = 2;
  RCC_OscInitStruct.PLL.PLLRGE = RCC_PLL1VCIRANGE_3;
  RCC_OscInitStruct.PLL.PLLVCOSEL = RCC_PLL1VCOWIDE;
  RCC_OscInitStruct.PLL.PLLFRACN = 6144;
  if (HAL_RCC_OscConfig(&RCC_OscInitStruct) != HAL_OK)
  {
    Error_Handler();
  }

  /** Initializes the CPU, AHB and APB buses clocks
  */
  RCC_ClkInitStruct.ClockType = RCC_CLOCKTYPE_HCLK|RCC_CLOCKTYPE_SYSCLK
                              |RCC_CLOCKTYPE_PCLK1|RCC_CLOCKTYPE_PCLK2
                              |RCC_CLOCKTYPE_D3PCLK1|RCC_CLOCKTYPE_D1PCLK1;
  RCC_ClkInitStruct.SYSCLKSource = RCC_SYSCLKSOURCE_PLLCLK;
  RCC_ClkInitStruct.SYSCLKDivider = RCC_SYSCLK_DIV1;
  RCC_ClkInitStruct.AHBCLKDivider = RCC_HCLK_DIV2;
  RCC_ClkInitStruct.APB3CLKDivider = RCC_APB3_DIV2;
  RCC_ClkInitStruct.APB1CLKDivider = RCC_APB1_DIV2;
  RCC_ClkInitStruct.APB2CLKDivider = RCC_APB2_DIV2;
  RCC_ClkInitStruct.APB4CLKDivider = RCC_APB4_DIV2;

  if (HAL_RCC_ClockConfig(&RCC_ClkInitStruct, FLASH_LATENCY_3) != HAL_OK)
  {
    Error_Handler();
  }
  HAL_RCC_MCOConfig(RCC_MCO1, RCC_MCO1SOURCE_HSI, RCC_MCODIV_1);
}

void HAL_TIM_PeriodElapsedCallback(TIM_HandleTypeDef *htim)
{
  if (htim->Instance == TIM17)
  {
    HAL_IncTick();
  }
  /* USER CODE BEGIN Callback 1 */
  MY_TIM_PeriodElapsedCallback(htim);
  /* USER CODE END Callback 1 */
}

void Error_Handler(void)
{
  /* USER CODE BEGIN Error_Handler_Debug */
  /* User can add his own implementation to report the HAL error return state */
  __disable_irq();
  __HAL_TIM_SET_COMPARE(&htim8, TIM_CHANNEL_3, 0);
  HAL_NVIC_SystemReset();
  while (1)
  {
  }
  /* USER CODE END Error_Handler_Debug */
}

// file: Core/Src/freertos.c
/* USER CODE BEGIN Header */
/**
  ******************************************************************************
  * File Name          : freertos.c
  * Description        : Code for freertos applications
  ******************************************************************************
  * @attention
  *
  * Copyright (c) 2026 STMicroelectronics.
  * All rights reserved.
  *
  * This software is licensed under terms that can be found in the LICENSE file
  * in the root directory of this software component.
  * If no LICENSE file comes with this software, it is provided AS-IS.
  *
  ******************************************************************************
  */
/* USER CODE END Header */

#include "FreeRTOS.h"
#include "task.h"
#include "main.h"
#include "FreeRTOS.h"
#include "cmsis_os2.h"

/* USER CODE BEGIN Includes */
#include "USB_Service.h"
/* USER CODE END Includes */

/* Definitions for IMU */
osThreadId_t IMUHandle;
const osThreadAttr_t IMU_attributes = {
  .name = "IMU",
  .stack_size = 256 * 4,
  .priority = (osPriority_t) osPriorityRealtime,
};
/* Definitions for Motor */
osThreadId_t MotorHandle;
const osThreadAttr_t Motor_attributes = {
  .name = "Motor",
  .stack_size = 256 * 4,
  .priority = (osPriority_t) osPriorityAboveNormal,
};
/* Definitions for Command */
osThreadId_t CommandHandle;
const osThreadAttr_t Command_attributes = {
  .name = "Command",
  .stack_size = 128 * 4,
  .priority = (osPriority_t) osPriorityHigh1,
};
/* Definitions for Task01 */
osThreadId_t Task01Handle;
const osThreadAttr_t Task01_attributes = {
  .name = "Task01",
  .stack_size = 512 * 4,
  .priority = (osPriority_t) osPriorityNormal1,
};
/* Definitions for Task02 */
osThreadId_t Task02Handle;
const osThreadAttr_t Task02_attributes = {
  .name = "Task02",
  .stack_size = 512 * 4,
  .priority = (osPriority_t) osPriorityNormal2,
};

void IMU_Task(void *argument);
void Motor_Task(void *argument);
void Command_Task(void *argument);
void StartTask01(void *argument);
void StartTask02(void *argument);

extern void MX_USB_DEVICE_Init(void);
void MX_FREERTOS_Init(void); /* (MISRA C 2004 rule 8.1) */

void MX_FREERTOS_Init(void) {

  /* Create the thread(s) */
  /* creation of IMU */
  IMUHandle = osThreadNew(IMU_Task, NULL, &IMU_attributes);

  /* creation of Motor */
  MotorHandle = osThreadNew(Motor_Task, NULL, &Motor_attributes);

  /* creation of Command */
  CommandHandle = osThreadNew(Command_Task, NULL, &Command_attributes);

  /* creation of Task01 */
  Task01Handle = osThreadNew(StartTask01, NULL, &Task01_attributes);

  /* creation of Task02 */
  Task02Handle = osThreadNew(StartTask02, NULL, &Task02_attributes);

  /* USER CODE BEGIN RTOS_THREADS */
  /* add threads, ... */
  if (USB_ServiceStart() != USB_OK) Error_Handler();
  /* USER CODE END RTOS_THREADS */

}

__weak void IMU_Task(void *argument)
{
  /* init code for USB_DEVICE */
  MX_USB_DEVICE_Init();
  for(;;)
  {
    osDelay(1);
  }
}

__weak void Motor_Task(void *argument)
{
  for(;;)
  {
    osDelay(1);
  }
}

__weak void Command_Task(void *argument)
{
  for(;;)
  {
    osDelay(1);
  }
}

__weak void StartTask01(void *argument)
{
  for(;;)
  {
    osDelay(1);
  }
}

__weak void StartTask02(void *argument)
{
  for(;;)
  {
    osDelay(1);
  }
}
